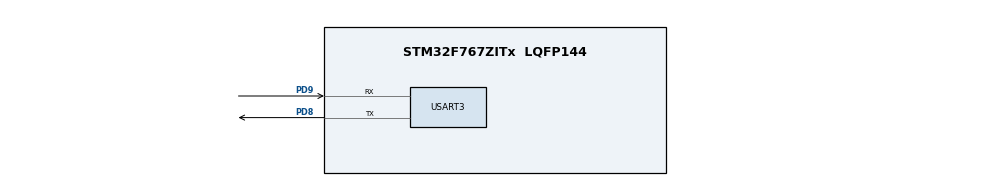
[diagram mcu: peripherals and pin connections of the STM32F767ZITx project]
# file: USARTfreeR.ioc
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FREERTOS.Queues01=USARTQueueFirstTask,10,QUEUE_t,0,Static,USARTQueueBuffer,USARTQueueControlBlock;USARTQueueSecondTask,10,QUEUE_t,0,Static,USARTQueueSecondTaskBuffer,USARTQueueSecondTaskControlBlock;USARTQueueThirdTask,10,QUEUE_t,0,Static,USARTQueueThirdTaskBuffer,USARTQueueThirdTaskControlBlock
FREERTOS.Tasks01=defaultTask,24,128,StartDefaultTask,Default,NULL,Dynamic,NULL,NULL;NothingTask,8,128,StartNothingTask,Default,NULL,Static,NothingTaskBuffer,NothingTaskControlBlock;UpperCaseTask,8,128,StartUpperCaseTask,Default,NULL,Static,UpperCaseTaskBuffer,UpperCaseTaskControlBlock;LowerCaseTask,8,128,StartLowerCaseTask,Default,NULL,Static,LowerCaseTaskBuffer,LowerCaseTaskControlBlock;ReceiveTask,8,128,StartReceiveTask,Default,NULL,Static,ReceiveTaskBuffer,ReceiveTaskControlBlock
Mcu.Family=STM32F7
Mcu.Name=STM32F767ZITx
Mcu.Package=LQFP144
NVIC.PriorityGroup=NVIC_PRIORITYGROUP_4
NVIC.TIM6_DAC_IRQn=true\:15\:0\:false\:false\:true\:false\:false\:true
NVIC.TimeBase=TIM6_DAC_IRQn
NVIC.TimeBaseIP=TIM6
NVIC.USART3_IRQn=true\:5\:0\:false\:false\:true\:true\:true\:true
PA13.Mode=Serial_Wire
PA13.Signal=SYS_JTMS-SWDIO
PA14.Mode=Serial_Wire
PA14.Signal=SYS_JTCK-SWCLK
PD8.Mode=Asynchronous
PD8.Signal=USART3_TX
PD9.Mode=Asynchronous
PD9.Signal=USART3_RX
ProjectManager.HeapSize=0x200
ProjectManager.StackSize=0x400
ProjectManager.TargetToolchain=STM32CubeIDE
RCC.HSE_VALUE=25000000
RCC.HSI_VALUE=16000000
RCC.LSE_VALUE=32768
RCC.USBFreq_Value=96000000
RCC.VCOOutputFreq_Value=192000000
USART3.VirtualMode-Asynchronous=VM_ASYNC
VP_FREERTOS_VS_CMSIS_V2.Mode=CMSIS_V2
VP_SYS_VS_tim6.Mode=TIM6
board=custom

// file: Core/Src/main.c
/* USER CODE BEGIN Header */
/**
  ******************************************************************************
  * @file           : main.c
  * @brief          : Main program body
  ******************************************************************************
  * @attention
  *
  * Copyright (c) 2022 STMicroelectronics.
  * All rights reserved.
  *
  * This software is licensed under terms that can be found in the LICENSE file
  * in the root directory of this software component.
  * If no LICENSE file comes with this software, it is provided AS-IS.
  *
  ******************************************************************************
  */
/* USER CODE END Header */
#include "main.h"
#include "cmsis_os.h"

/* USER CODE BEGIN Includes */
#include "string.h"
/* USER CODE END Includes */

typedef StaticTask_t osStaticThreadDef_t;
typedef StaticQueue_t osStaticMessageQDef_t;
/* USER CODE BEGIN PTD */

typedef struct
{
	char buf[5];
} QUEUE_t;

/* USER CODE END PTD */

UART_HandleTypeDef huart3;

/* Definitions for defaultTask */
osThreadId_t defaultTaskHandle;
const osThreadAttr_t defaultTask_attributes = {
  .name = "defaultTask",
  .stack_size = 128 * 4,
  .priority = (osPriority_t) osPriorityNormal,
};
/* Definitions for NothingTask */
osThreadId_t NothingTaskHandle;
uint32_t NothingTaskBuffer[ 128 ];
osStaticThreadDef_t NothingTaskControlBlock;
const osThreadAttr_t NothingTask_attributes = {
  .name = "NothingTask",
  .cb_mem = &NothingTaskControlBlock,
  .cb_size = sizeof(NothingTaskControlBlock),
  .stack_mem = &NothingTaskBuffer[0],
  .stack_size = sizeof(NothingTaskBuffer),
  .priority = (osPriority_t) osPriorityLow,
};
/* Definitions for UpperCaseTask */
osThreadId_t UpperCaseTaskHandle;
uint32_t UpperCaseTaskBuffer[ 128 ];
osStaticThreadDef_t UpperCaseTaskControlBlock;
const osThreadAttr_t UpperCaseTask_attributes = {
  .name = "UpperCaseTask",
  .cb_mem = &UpperCaseTaskControlBlock,
  .cb_size = sizeof(UpperCaseTaskControlBlock),
  .stack_mem = &UpperCaseTaskBuffer[0],
  .stack_size = sizeof(UpperCaseTaskBuffer),
  .priority = (osPriority_t) osPriorityLow,
};
/* Definitions for LowerCaseTask */
osThreadId_t LowerCaseTaskHandle;
uint32_t LowerCaseTaskBuffer[ 128 ];
osStaticThreadDef_t LowerCaseTaskControlBlock;
const osThreadAttr_t LowerCaseTask_attributes = {
  .name = "LowerCaseTask",
  .cb_mem = &LowerCaseTaskControlBlock,
  .cb_size = sizeof(LowerCaseTaskControlBlock),
  .stack_mem = &LowerCaseTaskBuffer[0],
  .stack_size = sizeof(LowerCaseTaskBuffer),
  .priority = (osPriority_t) osPriorityLow,
};
/* Definitions for ReceiveTask */
osThreadId_t ReceiveTaskHandle;
uint32_t ReceiveTaskBuffer[ 128 ];
osStaticThreadDef_t ReceiveTaskControlBlock;
const osThreadAttr_t ReceiveTask_attributes = {
  .name = "ReceiveTask",
  .cb_mem = &ReceiveTaskControlBlock,
  .cb_size = sizeof(ReceiveTaskControlBlock),
  .stack_mem = &ReceiveTaskBuffer[0],
  .stack_size = sizeof(ReceiveTaskBuffer),
  .priority = (osPriority_t) osPriorityLow,
};
/* Definitions for USARTQueueFirstTask */
osMessageQueueId_t USARTQueueFirstTaskHandle;
uint8_t USARTQueueBuffer[ 10 * sizeof( QUEUE_t ) ];
osStaticMessageQDef_t USARTQueueControlBlock;
const osMessageQueueAttr_t USARTQueueFirstTask_attributes = {
  .name = "USARTQueueFirstTask",
  .cb_mem = &USARTQueueControlBlock,
  .cb_size = sizeof(USARTQueueControlBlock),
  .mq_mem = &USARTQueueBuffer,
  .mq_size = sizeof(USARTQueueBuffer)
};
/* Definitions for USARTQueueSecondTask */
osMessageQueueId_t USARTQueueSecondTaskHandle;
uint8_t USARTQueueSecondTaskBuffer[ 10 * sizeof( QUEUE_t ) ];
osStaticMessageQDef_t USARTQueueSecondTaskControlBlock;
const osMessageQueueAttr_t USARTQueueSecondTask_attributes = {
  .name = "USARTQueueSecondTask",
  .cb_mem = &USARTQueueSecondTaskControlBlock,
  .cb_size = sizeof(USARTQueueSecondTaskControlBlock),
  .mq_mem = &USARTQueueSecondTaskBuffer,
  .mq_size = sizeof(USARTQueueSecondTaskBuffer)
};
/* Definitions for USARTQueueThirdTask */
osMessageQueueId_t USARTQueueThirdTaskHandle;
uint8_t USARTQueueThirdTaskBuffer[ 10 * sizeof( QUEUE_t ) ];
osStaticMessageQDef_t USARTQueueThirdTaskControlBlock;
const osMessageQueueAttr_t USARTQueueThirdTask_attributes = {
  .name = "USARTQueueThirdTask",
  .cb_mem = &USARTQueueThirdTaskControlBlock,
  .cb_size = sizeof(USARTQueueThirdTaskControlBlock),
  .mq_mem = &USARTQueueThirdTaskBuffer,
  .mq_size = sizeof(USARTQueueThirdTaskBuffer)
};

void SystemClock_Config(void);
static void MX_GPIO_Init(void);
static void MX_USART3_UART_Init(void);
void StartDefaultTask(void *argument);
void StartNothingTask(void *argument);
void StartUpperCaseTask(void *argument);
void StartLowerCaseTask(void *argument);
void StartReceiveTask(void *argument);

/* USER CODE BEGIN 0 */
char buff[5] = {};
uint8_t flag;
/* USER CODE END 0 */

int main(void)
{

  /* MCU Configuration--------------------------------------------------------*/

  /* Reset of all peripherals, Initializes the Flash interface and the Systick. */
  HAL_Init();

  /* Configure the system clock */
  SystemClock_Config();

  /* Initialize all configured peripherals */
  MX_GPIO_Init();
  MX_USART3_UART_Init();

  /* Init scheduler */
  osKernelInitialize();

  /* Create the queue(s) */
  /* creation of USARTQueueFirstTask */
  USARTQueueFirstTaskHandle = osMessageQueueNew (10, sizeof(QUEUE_t), &USARTQueueFirstTask_attributes);

  /* creation of USARTQueueSecondTask */
  USARTQueueSecondTaskHandle = osMessageQueueNew (10, sizeof(QUEUE_t), &USARTQueueSecondTask_attributes);

  /* creation of USARTQueueThirdTask */
  USARTQueueThirdTaskHandle = osMessageQueueNew (10, sizeof(QUEUE_t), &USARTQueueThirdTask_attributes);

  /* Create the thread(s) */
  /* creation of defaultTask */
  defaultTaskHandle = osThreadNew(StartDefaultTask, NULL, &defaultTask_attributes);

  /* creation of NothingTask */
  NothingTaskHandle = osThreadNew(StartNothingTask, NULL, &NothingTask_attributes);

  /* creation of UpperCaseTask */
  UpperCaseTaskHandle = osThreadNew(StartUpperCaseTask, NULL, &UpperCaseTask_attributes);

  /* creation of LowerCaseTask */
  LowerCaseTaskHandle = osThreadNew(StartLowerCaseTask, NULL, &LowerCaseTask_attributes);

  /* creation of ReceiveTask */
  ReceiveTaskHandle = osThreadNew(StartReceiveTask, NULL, &ReceiveTask_attributes);

  /* Start scheduler */
  osKernelStart();

  /* We should never get here as control is now taken by the scheduler */
  /* Infinite loop */
  while (1)
  {

  }
}

void SystemClock_Config(void)
{
  RCC_OscInitTypeDef RCC_OscInitStruct = {0};
  RCC_ClkInitTypeDef RCC_ClkInitStruct = {0};

  /** Configure the main internal regulator output voltage
  */
  __HAL_RCC_PWR_CLK_ENABLE();
  __HAL_PWR_VOLTAGESCALING_CONFIG(PWR_REGULATOR_VOLTAGE_SCALE3);
  /** Initializes the RCC Oscillators according to the specified parameters
  * in the RCC_OscInitTypeDef structure.
  */
  RCC_OscInitStruct.OscillatorType = RCC_OSCILLATORTYPE_HSI;
  RCC_OscInitStruct.HSIState = RCC_HSI_ON;
  RCC_OscInitStruct.HSICalibrationValue = RCC_HSICALIBRATION_DEFAULT;
  RCC_OscInitStruct.PLL.PLLState = RCC_PLL_NONE;
  if (HAL_RCC_OscConfig(&RCC_OscInitStruct) != HAL_OK)
  {
    Error_Handler();
  }
  /** Initializes the CPU, AHB and APB buses clocks
  */
  RCC_ClkInitStruct.ClockType = RCC_CLOCKTYPE_HCLK|RCC_CLOCKTYPE_SYSCLK
                              |RCC_CLOCKTYPE_PCLK1|RCC_CLOCKTYPE_PCLK2;
  RCC_ClkInitStruct.SYSCLKSource = RCC_SYSCLKSOURCE_HSI;
  RCC_ClkInitStruct.AHBCLKDivider = RCC_SYSCLK_DIV1;
  RCC_ClkInitStruct.APB1CLKDivider = RCC_HCLK_DIV1;
  RCC_ClkInitStruct.APB2CLKDivider = RCC_HCLK_DIV1;

  if (HAL_RCC_ClockConfig(&RCC_ClkInitStruct, FLASH_LATENCY_0) != HAL_OK)
  {
    Error_Handler();
  }
}

static void MX_USART3_UART_Init(void)
{

  huart3.Instance = USART3;
  huart3.Init.BaudRate = 115200;
  huart3.Init.WordLength = UART_WORDLENGTH_8B;
  huart3.Init.StopBits = UART_STOPBITS_1;
  huart3.Init.Parity = UART_PARITY_NONE;
  huart3.Init.Mode = UART_MODE_TX_RX;
  huart3.Init.HwFlowCtl = UART_HWCONTROL_NONE;
  huart3.Init.OverSampling = UART_OVERSAMPLING_16;
  huart3.Init.OneBitSampling = UART_ONE_BIT_SAMPLE_DISABLE;
  huart3.AdvancedInit.AdvFeatureInit = UART_ADVFEATURE_NO_INIT;
  if (HAL_UART_Init(&huart3) != HAL_OK)
  {
    Error_Handler();
  }

}

static void MX_GPIO_Init(void)
{

  /* GPIO Ports Clock Enable */
  __HAL_RCC_GPIOD_CLK_ENABLE();
  __HAL_RCC_GPIOA_CLK_ENABLE();

}

/* USER CODE BEGIN 4 */
void HAL_UART_RxCpltCallback(UART_HandleTypeDef *huart)
{
          if(huart == &huart3)
          {
        	  flag = 1;
          }
}
/* USER CODE END 4 */

void StartDefaultTask(void *argument)
{
  for(;;)
  {
    osDelay(1);
  }
}

void StartNothingTask(void *argument)
{
  /* USER CODE BEGIN StartNothingTask */
	QUEUE_t msg;
  /* Infinite loop */
  for(;;)
  {
	  osMessageQueueGet(USARTQueueFirstTaskHandle, &msg, 0, osWaitForever);
	  HAL_UART_Transmit_IT(&huart3, (uint8_t*)msg.buf, 4);

	osDelay(1);
  }
  /* USER CODE END StartNothingTask */
}

void StartUpperCaseTask(void *argument)
{
  /* USER CODE BEGIN StartUpperCaseTask */
	QUEUE_t msg;
  /* Infinite loop */
  for(;;)
  {
	  osMessageQueueGet(USARTQueueSecondTaskHandle, &msg, 0, osWaitForever);
	  HAL_UART_Transmit_IT(&huart3, (uint8_t*)msg.buf, 4);
    osDelay(1);
  }
  /* USER CODE END StartUpperCaseTask */
}

void StartLowerCaseTask(void *argument)
{
  /* USER CODE BEGIN StartLowerCaseTask */
    QUEUE_t msg;
  /* Infinite loop */
  for(;;)
  {
	  osMessageQueueGet(USARTQueueThirdTaskHandle, &msg, 0, osWaitForever);
	  HAL_UART_Transmit_IT(&huart3, (uint8_t*)msg.buf, 4);

	  osDelay(1);
  }
  /* USER CODE END StartLowerCaseTask */
}

void StartReceiveTask(void *argument)
{
  /* USER CODE BEGIN StartReceiveTask */
	QUEUE_t msg;
  /* Infinite loop */
  for(;;)
  {
	  HAL_UART_Receive_IT(&huart3, (uint8_t*)buff, 5);

	  	if (flag)
	  	{
	  		if(buff[0] == '1'){
	  		strcpy(msg.buf,buff+1);
	  		osMessageQueuePut(USARTQueueFirstTaskHandle, &msg, 0, osWaitForever);
	  		}
	  		else if (buff[0] == '2')
	  		{
	  			for(int i=1; i<strlen(buff); i++)
			  	  {
				  if(buff[i]>='a' && buff[i]<='z')
					  {
					  buff[i] = buff[i] - 32;
					  }
				  }

			strcpy(msg.buf,buff+1);
			osMessageQueuePut(USARTQueueSecondTaskHandle, &msg, 0, osWaitForever);
	  		}
	  		else if (buff[0] == '3')
	  		{
	  			for(int i=0; i<strlen(buff+1); i++)
				  {
				  if((buff+1)[i]>='A' && (buff+1)[i]<='Z')
				  	  {
					  (buff+1)[i] = (buff+1)[i] + 32;
				  	  }
				  }

			strcpy(msg.buf,buff+1);
			osMessageQueuePut(USARTQueueThirdTaskHandle, &msg, 0, osWaitForever);
	  		}

	  		flag = 0;
	  	}
    osDelay(1);
  }
  /* USER CODE END StartReceiveTask */
}

void HAL_TIM_PeriodElapsedCallback(TIM_HandleTypeDef *htim)
{
  if (htim->Instance == TIM6) {
    HAL_IncTick();
  }
}

void Error_Handler(void)
{
  __disable_irq();
  while (1)
  {
  }
}
